# S1C31D50 register map
Vendor: Epson; Series: S1C31D50; File version: 1.00
CPU: CM0PLUS r0p1, little endian, MPU, no FPU, VTOR, 2 interrupt priority bits
Registers are 16-bit, read-write, reset 0x0 unless marked. A register's access mark holds for its fields unless they carry their own. Offsets are from the block's base; [hi:lo] are bit positions; {n}, {i} and the like mark numbered series; 'fields as' and 'values as' point back to an identical list.

## I2C_0 — I2C channel 0 control
Base 0x002003C0
Same registers: I2C_1 0x002006C0, I2C_2 0x002006E0
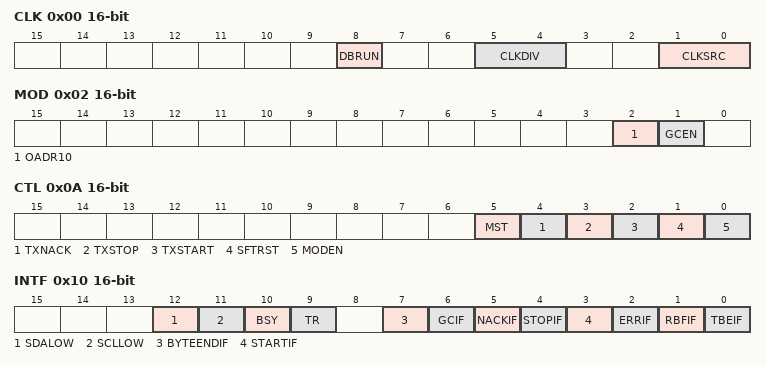
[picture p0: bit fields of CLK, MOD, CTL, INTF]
0x00 CLK — Clock Control Register
  [8] DBRUN — Enable clock on debug mode
    0=DISABLE; 1=ENABLE
  [5:4] CLKDIV — Clock division select
  [1:0] CLKSRC — Clock source select (can be write protected)
    0=IOSC; 1=OSC1; 2=OSC3; 3=EXOSC
0x02 MOD — Mode Register
  [2] OADR10 — Own addressing mode select
    0=7_BIT (7-bit address); 1=10_BIT (10-bit address)
  [1] GCEN — General call response enable
    0=DISABLE (Do not respond to general calls); 1=ENABLE (Respond to general calls)
0x04 BR reset 0x7F — Baud Rate Register
  [6:0] BRT range 0x1..0x7F — Baud rate setting
0x08 OADR — Own Address Register
  [9:0] OADR — I2C own address
0x0A CTL — Control Register
  [5] MST — Master Mode Select
    0=SLAVE (Slave mode); 1=MASTER (Master mode)
  [4] TXNACK write-1-sets — Transmit NACK Request
    on write: 0=NON (No effect); 1=ISSUE (Issue a NACK) | on read: 0=NO_PENDING (No Transmit NACK Pending); 1=PENDING (Transmit NACK Pending)
  [3] TXSTOP write-1-sets — Transmit STOP Condition Request in master mode
    on write: 0=NON (No effect); 1=ISSUE (Issue a STOP condition) | on read: 0=NO_PENDING (No Generate STOP Pending); 1=PENDING (Generate STOP Pending)
  [2] TXSTART write-1-sets — Transmit START Condition Request in master mode
    on write: 0=NON (No effect); 1=ISSUE (Issue a START condition) | on read: 0=NO_PENDING (No Generate START Pending); 1=PENDING (Generate START Pending)
  [1] SFTRST write-1-sets — Soft reset
    on write: 0=NON (No effect); 1=ISSUE (Issue software reset) | on read: 0=NO_PENDING (No Reset Pending); 1=PENDING (Reset Pending)
  [0] MODEN — I2C enable
    0=DISABLE (Disable I2C operations (The operating clock is stopped)); 1=ENABLE (Enable I2C operations (The operating clock is supplied))
0x0C TXD — Transmit Data Register
  [7:0] TXD — Transmit buffer
0x0E RXD ro — Receive Data Register
  [7:0] RXD — Receive buffer
0x10 INTF — Status and Interrupt Flag Register
  [12] SDALOW ro — SDA low flag
    0=LOW (SDA is low); 1=HIGH (SDA is high)
  [11] SCLLOW ro — SCL low flag
    0=LOW (SCL is low); 1=HIGH (SCL is high)
  [10] BSY ro — Busy flag
    0=IDLE (I2C bus free); 1=BUSY (I2C bus busy)
  [9] TR ro — Transmitter/Receiver
    0=RX (Reception mode); 1=TX (Transmission mode)
  [7] BYTEENDIF write-1-clears — Byte Transmit/Receive complete (includes ACK/NACK) interrupt flag
    0=NOT_OCCURED (No cause of interrupt occurred); 1=OCCURED (Cause of interrupt occurred)
  [6] GCIF write-1-clears — General Call address received interrupt flag
    values as BYTEENDIF
  [5] NACKIF write-1-clears — Not-acknowledge received interrupt flag
    values as BYTEENDIF
  [4] STOPIF write-1-clears — Stop condition end/detect interrupt flag
    values as BYTEENDIF
  [3] STARTIF write-1-clears — Start condition end/detect interrupt flag
    values as BYTEENDIF
  [2] ERRIF write-1-clears — Error detection interrupt flag
    values as BYTEENDIF
  [1] RBFIF ro — Receive buffer full interrupt flag (cleared by reading I2C0RXD register)
    values as BYTEENDIF
  [0] TBEIF ro — Transmit buffer empty interrupt flag (cleared by writing I2C0TXD register)
    values as BYTEENDIF
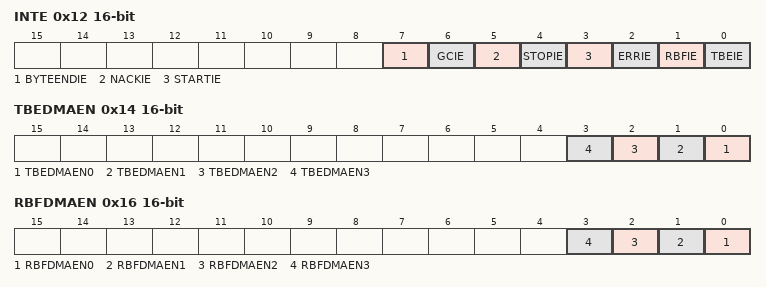
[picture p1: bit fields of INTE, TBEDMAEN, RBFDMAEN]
0x12 INTE — Interrupt Enable Register
  [all] fields
    0=DISABLE; 1=ENABLE
  [7] BYTEENDIE — Byte Transmit/Receive complete (includes ACK/NACK) interrupt enable
  [6] GCIE — General Call address received interrupt enable
  [5] NACKIE — Not-acknowledge received interrupt enable
  [4] STOPIE — Stop condition end/detect interrupt enable
  [3] STARTIE — Start condition end/detect interrupt enable
  [2] ERRIE — Error interrupt flag in normal mode enable
  [1] RBFIE — Receive buffer full interrupt enable
  [0] TBEIE — Transmit buffer empty interrupt enable
0x14 TBEDMAEN — TBE DMA Enable Register
  [all] fields
    0=DISABLE; 1=ENABLE
  [n] TBEDMAEN{n} (n=0..3) — TBE DMA ch{n} request enable
0x16 RBFDMAEN — RBF DMA Enable Register
  [all] fields
    0=DISABLE; 1=ENABLE
  [n] RBFDMAEN{n} (n=0..3) — RBF DMA ch{n} request enable
